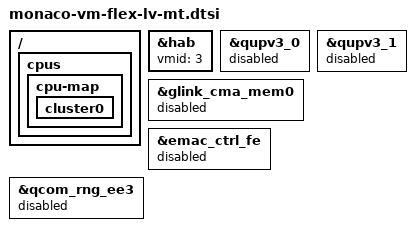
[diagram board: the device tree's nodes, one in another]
// SPDX-License-Identifier: BSD-3-Clause
/*
 * Copyright (c) Qualcomm Technologies, Inc. and/or its subsidiaries.
 */

&hab {
	vmid = <3>;
};

&qupv3_0 {
	status = "disabled";
};

&qupv3_1 {
	status = "disabled";
};

&glink_cma_mem0 {
	status = "disabled";
};

&emac_ctrl_fe {
	status = "disabled";
};

&qcom_rng_ee3 {
	status = "disabled";
};

/ {
	cpus {
		/delete-node/ opp-table1;
		/delete-node/ cpu@2;
		/delete-node/ cpu@3;
		/delete-node/ cpu@4;
		/delete-node/ cpu@5;
		/delete-node/ cpu@6;
		/delete-node/ cpu@7;

		cpu-map {
			cluster0 {
				/delete-node/ core2;
				/delete-node/ core3;
			};

			/delete-node/ cluster1;
		};
	};
};
